# STM32L4x1 register map
File version: 2.5
CPU: CM4 r0p1, little endian, MPU, FPU, 4 interrupt priority bits
Registers are 32-bit, read-write, reset 0x0 unless marked. A register's access mark holds for its fields unless they carry their own. Offsets are from the block's base; [hi:lo] are bit positions; {n}, {i} and the like mark numbered series.

## GPIOA — General-purpose I/Os
Base 0x48000000
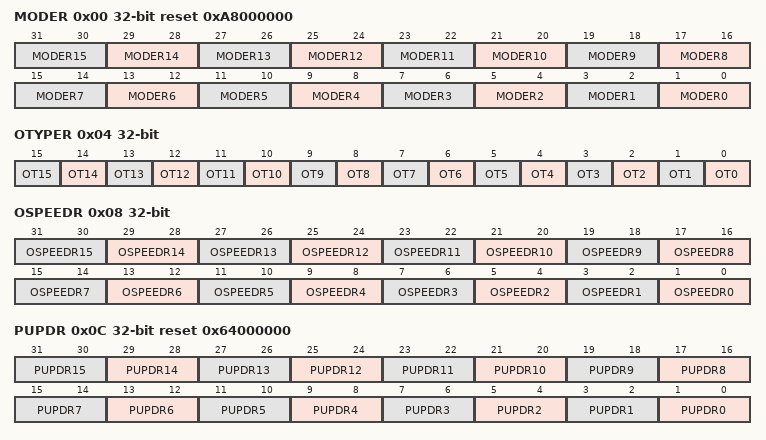
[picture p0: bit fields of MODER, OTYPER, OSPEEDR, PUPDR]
0x00 MODER reset 0xA8000000 — GPIO port mode register
  [2n+1:2n] MODER{n} (n=0..15) — Port x configuration pin {n}
    0=Input mode (reset state); 1=Output (General purpose output mode); 2=Alternate function mode; 3=Analog mode
0x04 OTYPER — GPIO port output type register
  [n] OT{n} (n=0..15) — Port x configuration pin {n}
    0=PushPull (Output push-pull (reset state)); 1=OpenDrain (Output open-drain)
0x08 OSPEEDR — GPIO port output speed register
  [2n+1:2n] OSPEEDR{n} (n=0..15) — Port x configuration pin {n}
    0=LowSpeed; 1=MediumSpeed; 2=HighSpeed; 3=VeryHighSpeed
0x0C PUPDR reset 0x64000000 — GPIO port pull-up/pull-down register
  [2n+1:2n] PUPDR{n} (n=0..15) — Port x configuration pin {n}
    0=Floating (No pull-up, pull-down); 1=PullUp; 2=PullDown
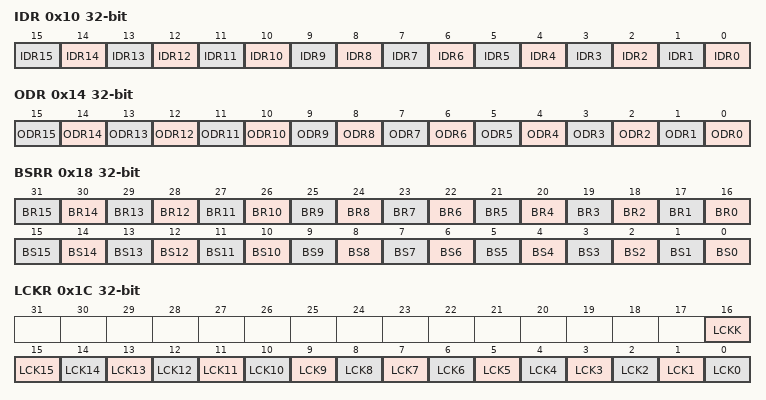
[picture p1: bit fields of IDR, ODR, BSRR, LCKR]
0x10 IDR ro — GPIO port input data register
  [n] IDR{n} (n=0..15) — Port input data pin {n}
    0=Low (Input is logic low); 1=High (Input is logic high)
0x14 ODR — GPIO port output data register
  [n] ODR{n} (n=0..15) — Port output data pin {n}
    0=Low (Set output to logic low); 1=High (Set output to logic high)
0x18 BSRR wo — GPIO port bit set/reset register
  [n+16] BR{n} (n=0..15) — Port x reset pin {n}
    1=Resets the corresponding ODRx bit
  [n] BS{n} (n=0..15) — Port x set pin {n}
    1=Set (Sets the corresponding ODRx bit)
0x1C LCKR — GPIO port configuration lock register
  [16] LCKK — Port x lock bit y (y= 0..15)
    0=NotActive (Port configuration lock key not active); 1=Active (Port configuration lock key active)
  [n] LCK{n} (n=0..15) — Port x lock pin {n}
    0=Unlocked (Port configuration not locked); 1=Locked (Port configuration locked)
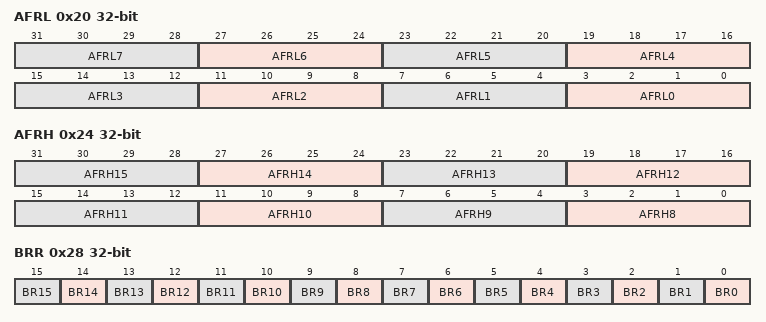
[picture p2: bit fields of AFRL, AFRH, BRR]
0x20 AFRL — GPIO alternate function low register
  [3:0] AFR{x} (x=L0,L1,L2,L3,L4,L5,L6,L7; step 4) — Alternate function selection for port x bit y (y = 0..7)
    {v}=AF{v} (v=0..15)
0x24 AFRH — GPIO alternate function high register
  [3:0] AFR{x} (x=H8,H9,H10,H11,H12,H13,H14,H15; step 4) — Alternate function selection for port x bit y (y = 8..15)
    {v}=AF{v} (v=0..15)
0x28 BRR access not given — GPIO port bit reset register
  [n] BR{n} (n=0..15) — Port x reset pin {n}
    on write: 0=No action on the corresponding ODx bit; 1=Reset the ODx bit

## GPIOB — General-purpose I/Os
Base 0x48000400
Registers as GPIOA; these are added or differ:
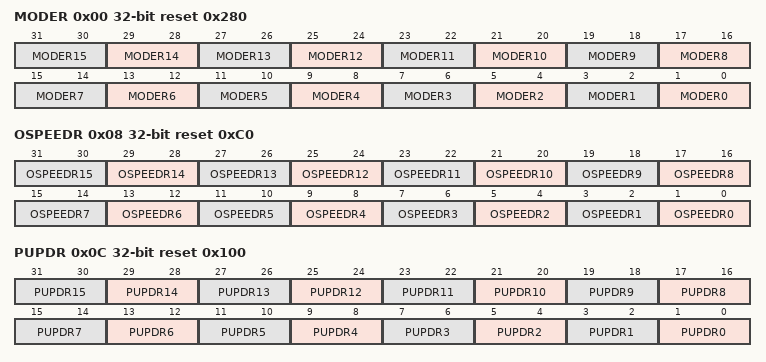
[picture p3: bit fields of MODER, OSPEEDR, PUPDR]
0x00 MODER reset 0x280 — GPIO port mode register
  [2n+1:2n] MODER{n} (n=0..15) — Port x configuration pin {n}
    0=Input mode (reset state); 1=Output (General purpose output mode); 2=Alternate function mode; 3=Analog mode
0x08 OSPEEDR reset 0xC0 — GPIO port output speed register
  [2n+1:2n] OSPEEDR{n} (n=0..15) — Port x configuration pin {n}
    0=LowSpeed; 1=MediumSpeed; 2=HighSpeed; 3=VeryHighSpeed
0x0C PUPDR reset 0x100 — GPIO port pull-up/pull-down register
  [2n+1:2n] PUPDR{n} (n=0..15) — Port x configuration pin {n}
    0=Floating (No pull-up, pull-down); 1=PullUp; 2=PullDown

## GPIOC — General-purpose I/Os
Base 0x48000800
Same registers: GPIOD 0x48000C00, GPIOE 0x48001000, GPIOF 0x48001400, GPIOG 0x48001800, GPIOH 0x48001C00
Registers as GPIOA; these are added or differ:
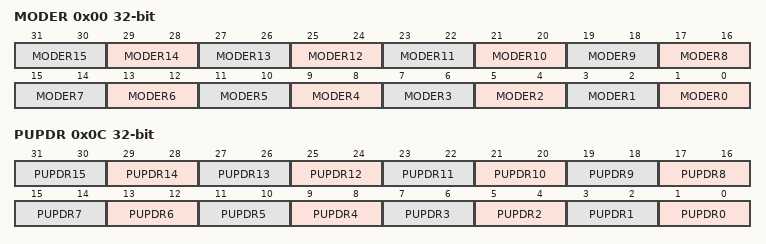
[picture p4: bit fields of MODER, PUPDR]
0x00 MODER — GPIO port mode register
  [2n+1:2n] MODER{n} (n=0..15) — Port x configuration pin {n}
    0=Input mode (reset state); 1=Output (General purpose output mode); 2=Alternate function mode; 3=Analog mode
0x0C PUPDR — GPIO port pull-up/pull-down register
  [2n+1:2n] PUPDR{n} (n=0..15) — Port x configuration pin {n}
    0=Floating (No pull-up, pull-down); 1=PullUp; 2=PullDown

## TIM6 — Basic-timers
Base 0x40001000
Same registers: TIM7 0x40001400
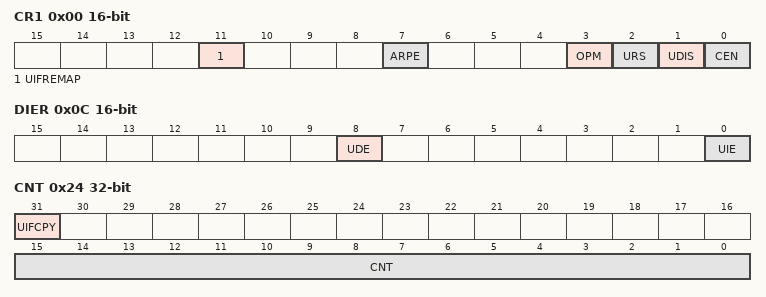
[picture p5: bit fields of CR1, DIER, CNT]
0x00 CR1 16-bit — control register 1
  [11] UIFREMAP — UIF status bit remapping
  [7] ARPE — Auto-reload preload enable
    0=Disabled (TIMx_APRR register is not buffered); 1=Enabled (TIMx_APRR register is buffered)
  [3] OPM — One-pulse mode
    0=Disabled (Counter is not stopped at update event); 1=Enabled (Counter stops counting at the next update event (clearing the CEN bit))
  [2] URS — Update request source
    0=AnyEvent (Any of counter overflow/underflow, setting UG, or update through slave mode, generates an update interrupt or DMA request); 1=CounterOnly (Only counter overflow/underflow generates an update interrupt or DMA request)
  [1] UDIS — Update disable
    0=Enabled (Update event enabled); 1=Disabled (Update event disabled)
  [0] CEN — Counter enable
    0=Disabled (Counter disabled); 1=Enabled (Counter enabled)
0x04 CR2 16-bit — control register 2
  [6:4] MMS — Master mode selection
    0=Reset (Use UG bit from TIMx_EGR register); 1=Enable (Use CNT bit from TIMx_CEN register); 2=Update (Use the update event)
0x0C DIER 16-bit — DMA/Interrupt enable register
  [8] UDE — Update DMA request enable
    0=Disabled (Update DMA request disabled); 1=Enabled (Update DMA request enabled)
  [0] UIE — Update interrupt enable
    0=Disabled (Update interrupt disabled); 1=Enabled (Update interrupt enabled)
0x10 SR 16-bit — status register
  [0] UIF write-0-clears — Update interrupt flag
    on read: 0=NoUpdateOccurred; 1=UpdatePending (Update interrupt pending) | on write: 0=Clear flag
0x14 EGR wo — event generation register
  [0] UG — Update generation
    1=Update (Re-initializes the timer counter and generates an update of the registers.)
0x24 CNT access per field — counter
  [31] UIFCPY ro — UIF Copy
  [15:0] CNT rw — Low counter value
0x24 CNT16 16-bit (alternate view of CNT) — 16-bit counter register
  [15:0] CNT — counter value
0x28 PSC 16-bit — prescaler
  [15:0] PSC — Prescaler value
0x2C ARR 16-bit reset 0xFFFF — auto-reload register
  [15:0] ARR — Prescaler value
